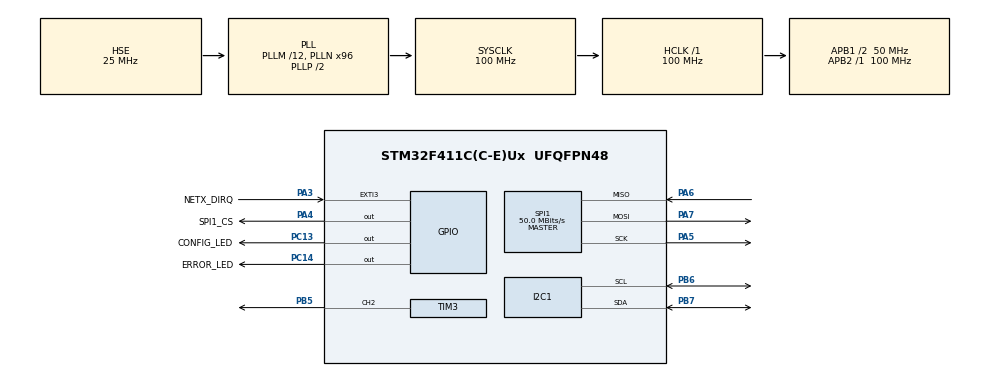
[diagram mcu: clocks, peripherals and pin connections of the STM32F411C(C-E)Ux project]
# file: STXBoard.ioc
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Dma.I2C1_TX.2.Direction=DMA_MEMORY_TO_PERIPH
Dma.I2C1_TX.2.FIFOMode=DMA_FIFOMODE_DISABLE
Dma.I2C1_TX.2.Instance=DMA1_Stream1
Dma.I2C1_TX.2.MemDataAlignment=DMA_MDATAALIGN_BYTE
Dma.I2C1_TX.2.MemInc=DMA_MINC_ENABLE
Dma.I2C1_TX.2.Mode=DMA_NORMAL
Dma.I2C1_TX.2.PeriphDataAlignment=DMA_PDATAALIGN_BYTE
Dma.I2C1_TX.2.PeriphInc=DMA_PINC_DISABLE
Dma.I2C1_TX.2.Priority=DMA_PRIORITY_LOW
Dma.Request0=SPI1_RX
Dma.Request1=SPI1_TX
Dma.Request2=I2C1_TX
Dma.Request3=TIM3_CH2
Dma.SPI1_RX.0.Direction=DMA_PERIPH_TO_MEMORY
Dma.SPI1_RX.0.FIFOMode=DMA_FIFOMODE_ENABLE
Dma.SPI1_RX.0.FIFOThreshold=DMA_FIFO_THRESHOLD_FULL
Dma.SPI1_RX.0.Instance=DMA2_Stream0
Dma.SPI1_RX.0.MemBurst=DMA_MBURST_SINGLE
Dma.SPI1_RX.0.MemDataAlignment=DMA_MDATAALIGN_BYTE
Dma.SPI1_RX.0.MemInc=DMA_MINC_ENABLE
Dma.SPI1_RX.0.Mode=DMA_NORMAL
Dma.SPI1_RX.0.PeriphBurst=DMA_PBURST_SINGLE
Dma.SPI1_RX.0.PeriphDataAlignment=DMA_PDATAALIGN_BYTE
Dma.SPI1_RX.0.PeriphInc=DMA_PINC_DISABLE
Dma.SPI1_RX.0.Priority=DMA_PRIORITY_MEDIUM
Dma.SPI1_TX.1.Direction=DMA_MEMORY_TO_PERIPH
Dma.SPI1_TX.1.FIFOMode=DMA_FIFOMODE_ENABLE
Dma.SPI1_TX.1.FIFOThreshold=DMA_FIFO_THRESHOLD_FULL
Dma.SPI1_TX.1.Instance=DMA2_Stream3
Dma.SPI1_TX.1.MemBurst=DMA_MBURST_SINGLE
Dma.SPI1_TX.1.MemDataAlignment=DMA_MDATAALIGN_BYTE
Dma.SPI1_TX.1.MemInc=DMA_MINC_ENABLE
Dma.SPI1_TX.1.Mode=DMA_NORMAL
Dma.SPI1_TX.1.PeriphBurst=DMA_PBURST_SINGLE
Dma.SPI1_TX.1.PeriphDataAlignment=DMA_PDATAALIGN_BYTE
Dma.SPI1_TX.1.PeriphInc=DMA_PINC_DISABLE
Dma.SPI1_TX.1.Priority=DMA_PRIORITY_MEDIUM
Dma.TIM3_CH2.3.Direction=DMA_MEMORY_TO_PERIPH
Dma.TIM3_CH2.3.FIFOMode=DMA_FIFOMODE_DISABLE
Dma.TIM3_CH2.3.Instance=DMA1_Stream5
Dma.TIM3_CH2.3.MemDataAlignment=DMA_MDATAALIGN_HALFWORD
Dma.TIM3_CH2.3.MemInc=DMA_MINC_ENABLE
Dma.TIM3_CH2.3.Mode=DMA_NORMAL
Dma.TIM3_CH2.3.PeriphDataAlignment=DMA_PDATAALIGN_HALFWORD
Dma.TIM3_CH2.3.PeriphInc=DMA_PINC_DISABLE
Dma.TIM3_CH2.3.Priority=DMA_PRIORITY_LOW
I2C1.I2C_Mode=I2C_Fast
Mcu.Family=STM32F4
Mcu.Name=STM32F411C(C-E)Ux
Mcu.Package=UFQFPN48
NVIC.DMA1_Stream1_IRQn=true\:1\:0\:true\:false\:true\:false\:true\:false
NVIC.DMA1_Stream5_IRQn=true\:0\:0\:false\:false\:true\:false\:true\:true
NVIC.DMA2_Stream0_IRQn=true\:0\:0\:false\:false\:true\:false\:true\:false
NVIC.DMA2_Stream3_IRQn=true\:0\:0\:false\:false\:true\:false\:true\:false
NVIC.EXTI3_IRQn=true\:7\:0\:true\:false\:true\:true\:true\:false
NVIC.I2C1_EV_IRQn=true\:12\:0\:true\:false\:true\:true\:true\:false
NVIC.PriorityGroup=NVIC_PRIORITYGROUP_4
NVIC.SPI1_IRQn=true\:8\:0\:true\:false\:true\:true\:true\:false
NVIC.TIM1_BRK_TIM9_IRQn=true\:14\:0\:true\:false\:true\:false\:true\:true
NVIC.TimeBase=TIM1_BRK_TIM9_IRQn
NVIC.TimeBaseIP=TIM9
PA3.GPIO_Label=NETX_DIRQ
PA3.GPIO_ModeDefaultEXTI=GPIO_MODE_IT_FALLING
PA3.GPIO_PuPd=GPIO_PULLUP
PA3.Signal=GPXTI3
PA4.GPIO_Label=SPI1_CS
PA4.GPIO_Speed=GPIO_SPEED_FREQ_VERY_HIGH
PA4.PinState=GPIO_PIN_SET
PA4.Signal=GPIO_Output
PA5.GPIO_Speed=GPIO_SPEED_FREQ_VERY_HIGH
PA5.Mode=Full_Duplex_Master
PA5.Signal=SPI1_SCK
PA6.GPIO_Speed=GPIO_SPEED_FREQ_VERY_HIGH
PA6.Mode=Full_Duplex_Master
PA6.Signal=SPI1_MISO
PA7.GPIO_Speed=GPIO_SPEED_FREQ_VERY_HIGH
PA7.Mode=Full_Duplex_Master
PA7.Signal=SPI1_MOSI
PB5.Signal=S_TIM3_CH2
PB6.GPIO_Pu=GPIO_PULLUP
PB6.GPIO_Speed=GPIO_SPEED_FREQ_LOW
PB6.Mode=I2C
PB6.Signal=I2C1_SCL
PB7.GPIO_Pu=GPIO_PULLUP
PB7.GPIO_Speed=GPIO_SPEED_FREQ_LOW
PB7.Mode=I2C
PB7.Signal=I2C1_SDA
PC13-ANTI_TAMP.GPIO_Label=CONFIG_LED
PC13-ANTI_TAMP.Signal=GPIO_Output
PC14-OSC32_IN.GPIO_Label=ERROR_LED
PC14-OSC32_IN.Signal=GPIO_Output
PH0\ -\ OSC_IN.Mode=HSE-External-Oscillator
PH0\ -\ OSC_IN.Signal=RCC_OSC_IN
PH1\ -\ OSC_OUT.Mode=HSE-External-Oscillator
PH1\ -\ OSC_OUT.Signal=RCC_OSC_OUT
ProjectManager.HeapSize=0x200
ProjectManager.StackSize=0x400
ProjectManager.TargetToolchain=STM32CubeIDE
RCC.48MHZClocksFreq_Value=50000000
RCC.AHBFreq_Value=100000000
RCC.APB1CLKDivider=RCC_HCLK_DIV2
RCC.APB1Freq_Value=50000000
RCC.APB1TimFreq_Value=100000000
RCC.APB2Freq_Value=100000000
RCC.APB2TimFreq_Value=100000000
RCC.CortexFreq_Value=100000000
RCC.HCLKFreq_Value=100000000
RCC.HSE_VALUE=25000000
RCC.HSI_VALUE=16000000
RCC.LSE_VALUE=32768
RCC.PLLM=12
RCC.PLLN=96
RCC.PLLSourceVirtual=RCC_PLLSOURCE_HSE
RCC.SYSCLKFreq_VALUE=100000000
RCC.SYSCLKSource=RCC_SYSCLKSOURCE_PLLCLK
RCC.VCOOutputFreq_Value=200000000
SH.S_TIM3_CH2.0=TIM3_CH2,PWM Generation2 CH2
SPI1.BaudRatePrescaler=SPI_BAUDRATEPRESCALER_2
SPI1.CLKPhase=SPI_PHASE_2EDGE
SPI1.CLKPolarity=SPI_POLARITY_HIGH
SPI1.CalculateBaudRate=50.0 MBits/s
SPI1.Direction=SPI_DIRECTION_2LINES
SPI1.Mode=SPI_MODE_MASTER
SPI1.VirtualType=VM_MASTER
TIM3.Channel-PWM\ Generation2\ CH2=TIM_CHANNEL_2
TIM3.Period=125-1
VP_SYS_VS_tim9.Mode=TIM9
board=custom

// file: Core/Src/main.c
/* USER CODE BEGIN Header */
/**
  ******************************************************************************
  * @file           : main.c
  * @brief          : Main program body
  ******************************************************************************
  * @attention
  *
  * Copyright (c) 2024 STMicroelectronics.
  * All rights reserved.
  *
  * This software is licensed under terms that can be found in the LICENSE file
  * in the root directory of this software component.
  * If no LICENSE file comes with this software, it is provided AS-IS.
  *
  ******************************************************************************
  */
/* USER CODE END Header */
#include "main.h"
#include "dma.h"
#include "i2c.h"
#include "spi.h"
#include "tim.h"
#include "gpio.h"

/* USER CODE BEGIN Includes */
#include "app_manager.h"
/* USER CODE END Includes */

void SystemClock_Config(void);

/* USER CODE BEGIN 0 */
//static void netx90DemoTask(void *pvParameters);
/* USER CODE END 0 */

int main(void)
{

  /* MCU Configuration--------------------------------------------------------*/

  /* Reset of all peripherals, Initializes the Flash interface and the Systick. */
  HAL_Init();

  /* Configure the system clock */
  SystemClock_Config();

  /* Initialize all configured peripherals */
  MX_GPIO_Init();
  MX_DMA_Init();
  MX_SPI1_Init();
  MX_I2C1_Init();
  MX_TIM3_Init();
  /* USER CODE BEGIN 2 */
  HAL_Delay(10);

  AppManager_Init();
  AppManager_Run();
  /* USER CODE END 2 */

  /* Infinite loop */
  while (1)
  {

  }
}

void SystemClock_Config(void)
{
  RCC_OscInitTypeDef RCC_OscInitStruct = {0};
  RCC_ClkInitTypeDef RCC_ClkInitStruct = {0};

  /** Configure the main internal regulator output voltage
  */
  __HAL_RCC_PWR_CLK_ENABLE();
  __HAL_PWR_VOLTAGESCALING_CONFIG(PWR_REGULATOR_VOLTAGE_SCALE1);

  /** Initializes the RCC Oscillators according to the specified parameters
  * in the RCC_OscInitTypeDef structure.
  */
  RCC_OscInitStruct.OscillatorType = RCC_OSCILLATORTYPE_HSE;
  RCC_OscInitStruct.HSEState = RCC_HSE_ON;
  RCC_OscInitStruct.PLL.PLLState = RCC_PLL_ON;
  RCC_OscInitStruct.PLL.PLLSource = RCC_PLLSOURCE_HSE;
  RCC_OscInitStruct.PLL.PLLM = 12;
  RCC_OscInitStruct.PLL.PLLN = 96;
  RCC_OscInitStruct.PLL.PLLP = RCC_PLLP_DIV2;
  RCC_OscInitStruct.PLL.PLLQ = 4;
  if (HAL_RCC_OscConfig(&RCC_OscInitStruct) != HAL_OK)
  {
    Error_Handler();
  }

  /** Initializes the CPU, AHB and APB buses clocks
  */
  RCC_ClkInitStruct.ClockType = RCC_CLOCKTYPE_HCLK|RCC_CLOCKTYPE_SYSCLK
                              |RCC_CLOCKTYPE_PCLK1|RCC_CLOCKTYPE_PCLK2;
  RCC_ClkInitStruct.SYSCLKSource = RCC_SYSCLKSOURCE_PLLCLK;
  RCC_ClkInitStruct.AHBCLKDivider = RCC_SYSCLK_DIV1;
  RCC_ClkInitStruct.APB1CLKDivider = RCC_HCLK_DIV2;
  RCC_ClkInitStruct.APB2CLKDivider = RCC_HCLK_DIV1;

  if (HAL_RCC_ClockConfig(&RCC_ClkInitStruct, FLASH_LATENCY_3) != HAL_OK)
  {
    Error_Handler();
  }
}

void HAL_TIM_PeriodElapsedCallback(TIM_HandleTypeDef *htim)
{
  if (htim->Instance == TIM9)
  {
    HAL_IncTick();
  }
}

void Error_Handler(void)
{
  /* USER CODE BEGIN Error_Handler_Debug */
  /* User can add his own implementation to report the HAL error return state */
  __disable_irq();
  HAL_GPIO_WritePin(CONFIG_LED_GPIO_Port, CONFIG_LED_Pin, GPIO_PIN_RESET);
  HAL_GPIO_WritePin(ERROR_LED_GPIO_Port, ERROR_LED_Pin, GPIO_PIN_SET);
  while (1)
  {
  }
  /* USER CODE END Error_Handler_Debug */
}
